# PIC32MK0512MCF064 device description
Architecture: MIPS; Family: PIC32MK; Series: PIC32MK
Registers are 32-bit, read-write, no defined reset value unless marked. A register's access mark holds for its fields unless they carry their own. Offsets are from the block's base; [hi:lo] are bit positions; {n}, {i} and the like mark numbered series; 'fields as' and 'values as' point back to an identical list.

## DSCTRL
Instances: DSCTRL 0x1f8c0200 in periph_pb6_std
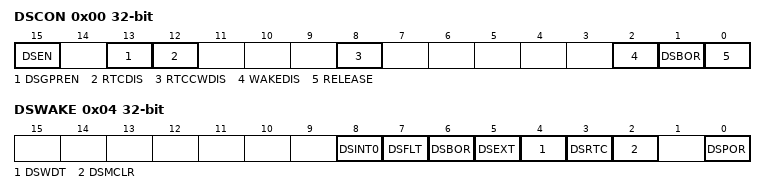
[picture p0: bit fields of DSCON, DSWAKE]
0x00 DSCON
  [15] DSEN, [13] DSGPREN, [12] RTCDIS, [8] RTCCWDIS, [2] WAKEDIS, [1] DSBOR, [0] RELEASE
0x04 DSWAKE
  [8] DSINT0, [7] DSFLT, [6] DSBOR, [5] DSEXT, [4] DSWDT, [3] DSRTC, [2] DSMCLR, [0] DSPOR
0x08 DSGPR0
  [31:0] DSGPR
{0xC+4i} DSGPR{i} (i=1..32)
  [31:0] DSGPR

## EEPROM
Instances: EEPROM 0x1f829000 in periph_pb2_std
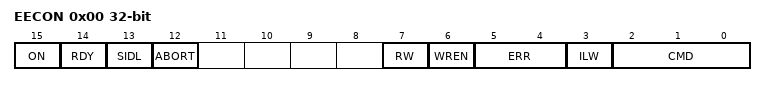
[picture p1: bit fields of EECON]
0x00 EECON — EEPROM CONTROL REGISTER
  [15] ON — Data EEPROM Power Control bit
    1=Data EEPROM is enabled; 0=Data EEPROM is disabled
  [14] RDY — Data EEPROM Ready bit
    1=Data EEPROM is ready for access; 0=Data EEPROM is not ready for access
  [13] SIDL — Stop in Idle Mode bit
    1=Discontinue operation when CPU enters in Idle mode; 0=Continue operation in Idle mode
  [12] ABORT — Data EEPROM Abort Operation Control bit
    1=Set by software to abort the on-going write command as soon as possible; 0=Data EEPROM panel is ready/Normal operation
  [7] RW — Start Command Execution Control bit
    1=(when WREN is 1)Start memory word program or erase command / (when WREN is 0)Cleared by hardware to indicate read operation has completed; 0=(when WREN is 1)Cleared by hardware to indicate program or erase operation has completed / (when WREN is 0)Cleared by hardware to indicate read operation has completed
  [6] WREN — Data EEPROM Write Enable Control bit
    1=Enables program or erase operations; 0=Disables program or erase of memory elements, and enables read operations
  [5:4] ERR — Data EEPROM Sequence Error Status bits
    3=A BOR event has occurred; 2=An attempted execution of a read or write operation with an invalid write OR command with a misaligned address (EEADDR(1:0) not 00); 1=A Bulk or Page Erase or a Word Program verify error has occurred; 0=No error condition
  [3] ILW — Data EEPROM Imminent Long Write Status bit
    1=The next write to the EEPROM address (held in the EEADDR register) will require more time (approx 20 ms) than usual; 0=The next write to the EEPROM address (held in the EEADDR register) will be a normal write cycle
  [2:0] CMD — Data EEPROM Command Selection bits
    4=Configuration register Write command (WREN bit must be set); 3=Data EEPROM memory Bulk Erase command (WREN bit must be set); 2=Data EEPROM memory Page Erase command (WREN bit must be set); 1=Word Write command (WREN bit must be set); 0=Word Read command (WREN bit must be clear)
0x10 EEKEY wo — EEPROM KEY REGISTER
  [15:0] EEKEY — Data EEPROM Key bits
0x20 EEADDR — EEPROM ADDRESS REGISTER
  [15:0] EEADR — Data EEPROM Address bits
0x30 EEDATA — EEPROM DATA REGISTER
  [31:0] EEDATA — Data EEPROM Data bits

## ICAP
Instances: ICAP 0x1f822000 in periph_pb2_std
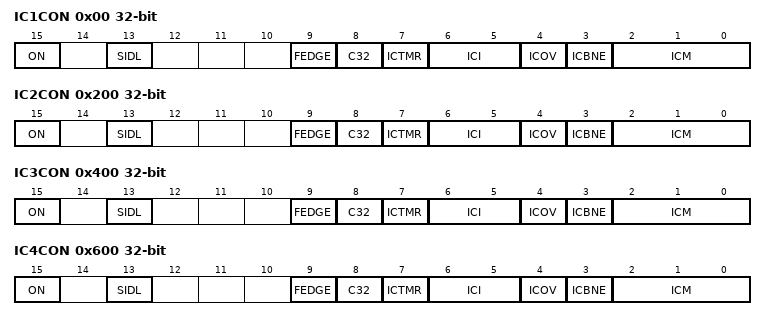
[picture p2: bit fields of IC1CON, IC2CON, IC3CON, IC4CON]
0x00 IC1CON — Input Capture x Control Register
  [15] ON — Input Capture Module Enable bit
    1=Module is enabled; 0=Disable and reset module
  [13] SIDL — Stop in Idle Control bit
    1=Halt in CPU Idle mode; 0=Continue to operate in CPU Idle mode
  [9] FEDGE — First Capture Edge Select bit
    1=Capture rising edge first; 0=Capture falling edge first
  [8] C32 — 32-bit Capture Select bit
    1=32-bit timer resource capture; 0=16-bit timer resource capture
  [7] ICTMR — Timer Select bit
    0=Timery is the counter source for capture; 1=Timerx is the counter source for capture
  [6:5] ICI — Interrupt Control bits
    3=Interrupt on every fourth capture event; 2=Interrupt on every third capture event; 1=Interrupt on every second capture event; 0=Interrupt on every capture event
  [4] ICOV — Input Capture Overflow Status Flag bit
    1=Input capture overflow is occurred; 0=No input capture overflow is occurred
  [3] ICBNE — Input Capture Buffer Not Empty Status bit
    1=Input capture buffer is not empty; at least one more capture value can be read; 0=Input capture buffer is empty
  [2:0] ICM — Input Capture Mode Select bits
    7=Interrupt-Only mode (only supported while in Sleep mode or Idle mode); 6=Simple Capture Event mode every edge; 5=Prescaled Capture Event mode every sixteenth rising edge; 4=Prescaled Capture Event mode every fourth rising edge; 3=Simple Capture Event mode every rising edge; 2=Simple Capture Event mode every falling edge; 1=Edge Detect mode every edge (rising and falling); 0=Input Capture module is disabled
0x10 IC1BUF ro
0x200 IC2CON — Input Capture x Control Register
  fields as IC1CON
0x210 IC2BUF ro
0x400 IC3CON — Input Capture x Control Register
  fields as IC1CON
0x410 IC3BUF ro
0x600 IC4CON — Input Capture x Control Register
  fields as IC1CON
0x610 IC4BUF ro
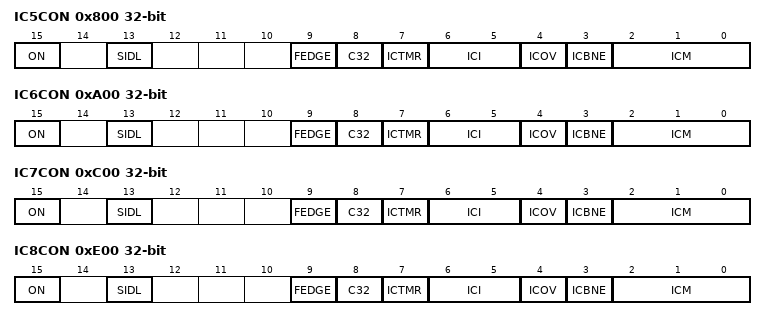
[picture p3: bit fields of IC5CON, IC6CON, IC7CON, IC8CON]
0x800 IC5CON — Input Capture x Control Register
  fields as IC1CON
0x810 IC5BUF ro
0xA00 IC6CON — Input Capture x Control Register
  fields as IC1CON
0xA10 IC6BUF ro
0xC00 IC7CON — Input Capture x Control Register
  fields as IC1CON
0xC10 IC7BUF ro
0xE00 IC8CON — Input Capture x Control Register
  fields as IC1CON
0xE10 IC8BUF ro
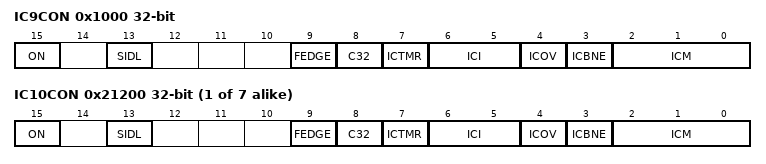
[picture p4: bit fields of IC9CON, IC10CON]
0x1000 IC9CON — Input Capture x Control Register
  fields as IC1CON
0x1010 IC9BUF ro
{0x1FE00+0x200*i} IC{i}CON (i=10..16) — Input Capture x Control Register
  fields as IC1CON
{0x1FE10+0x200*i} IC{i}BUF ro (i=10..16)

## Notices in the file
Copyright (c) 2017 Microchip Technology Inc.
SPDX-License-Identifier: Apache-2.0
Licensed under the Apache License, Version 2.0 (the "License");
you may not use this file except in compliance with the License.
You may obtain a copy of the License at
http://www.apache.org/licenses/LICENSE-2.0
Unless required by applicable law or agreed to in writing, software
distributed under the License is distributed on an "AS IS" BASIS,
WITHOUT WARRANTIES OR CONDITIONS OF ANY KIND, either express or implied.
See the License for the specific language governing permissions and
limitations under the License.
